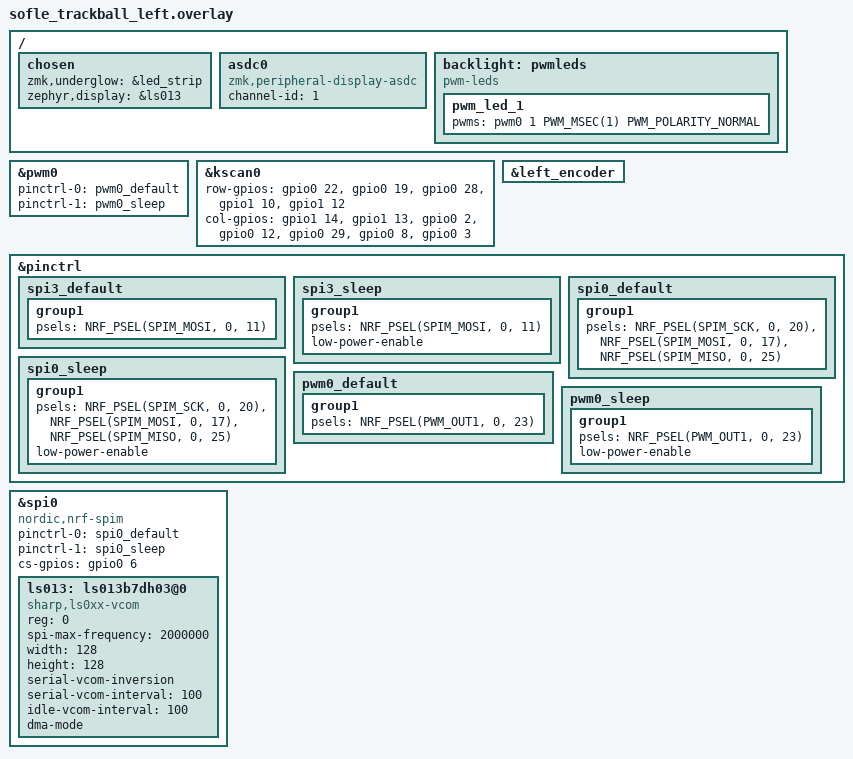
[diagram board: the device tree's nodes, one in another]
/*
 * Copyright (c) 2020 ZMK Contributors
 *
 * SPDX-License-Identifier: MIT
 */
#include <dt-bindings/zmk/input_transform.h>
#include <dt-bindings/led/led.h>
#include <behaviors/battery_history_request.dtsi>
#include "sofle_trackball.dtsi"

#include "rgb.dtsi"



/ {
    chosen {
        zmk,underglow = &led_strip;
        zephyr,display = &ls013;
    };

    asdc0: asdc0 {
        compatible = "zmk,peripheral-display-asdc";
        channel-id = <1>;
        status = "okay";
    };
backlight: pwmleds {
    compatible = "pwm-leds";
   // pwm_led_0: pwm_led_0 {
   //     pwms = <&pwm0 0 PWM_MSEC(1) PWM_POLARITY_NORMAL>;
  //  };
    pwm_led_1: pwm_led_1 {
        pwms = <&pwm0 1 PWM_MSEC(1) PWM_POLARITY_NORMAL>;
    };
  //  pwm_led_2: pwm_led_2 {
   //     pwms = <&pwm0 2 PWM_MSEC(1) PWM_POLARITY_NORMAL>;
  //  };
};


};

&pwm0 {
    status = "okay";
    pinctrl-0 = <&pwm0_default>;
    pinctrl-1 = <&pwm0_sleep>;
    pinctrl-names = "default", "sleep";
};
&kscan0 {
    row-gpios
                = <&gpio0 22 (GPIO_ACTIVE_HIGH | GPIO_PULL_DOWN)>
                , <&gpio0 19 (GPIO_ACTIVE_HIGH | GPIO_PULL_DOWN)>
                , <&gpio0 28 (GPIO_ACTIVE_HIGH | GPIO_PULL_DOWN)>
                , <&gpio1 10 (GPIO_ACTIVE_HIGH | GPIO_PULL_DOWN)>
                , <&gpio1 12 (GPIO_ACTIVE_HIGH | GPIO_PULL_DOWN)>
    ;
    col-gpios
                = <&gpio1 14 (GPIO_ACTIVE_HIGH)>
                , <&gpio1 13 (GPIO_ACTIVE_HIGH)>
                , <&gpio0 2 (GPIO_ACTIVE_HIGH)>
                , <&gpio0 12 (GPIO_ACTIVE_HIGH)>
                , <&gpio0 29 (GPIO_ACTIVE_HIGH)>
                , <&gpio0 8 (GPIO_ACTIVE_HIGH)>
                , <&gpio0 3 (GPIO_ACTIVE_HIGH)>
    ;
};




&left_encoder {
    status = "okay";
};



&pinctrl {

    spi3_default: spi3_default {
        group1 {
            psels = <NRF_PSEL(SPIM_MOSI, 0, 11)>;
        };
    };
    spi3_sleep: spi3_sleep {
        group1 {
            psels = <NRF_PSEL(SPIM_MOSI, 0, 11)>;
            low-power-enable;
        };
    };
    spi0_default: spi0_default {
        group1 {
            psels = <NRF_PSEL(SPIM_SCK, 0, 20)>,
                <NRF_PSEL(SPIM_MOSI, 0, 17)>,
                <NRF_PSEL(SPIM_MISO, 0, 25)>;
        };
    };

    spi0_sleep: spi0_sleep {
        group1 {
            psels = <NRF_PSEL(SPIM_SCK, 0, 20)>,
                <NRF_PSEL(SPIM_MOSI, 0, 17)>,
                <NRF_PSEL(SPIM_MISO, 0, 25)>;
            low-power-enable;
        };
    };
    // Other Pinctrl definitions go here
    pwm0_default: pwm0_default {
        group1 {
            psels =  <NRF_PSEL(PWM_OUT1, 0, 23)>; 
               
        };
    };
    pwm0_sleep: pwm0_sleep {
        group1 {
            psels =  <NRF_PSEL(PWM_OUT1, 0, 23)>; 
                  
            low-power-enable;
        };
    };

};





nice_view_spi: &spi0 {
    status = "okay";
    compatible = "nordic,nrf-spim";
    pinctrl-0 = <&spi0_default>;
    pinctrl-1 = <&spi0_sleep>;
    pinctrl-names = "default", "sleep";
    cs-gpios = <&gpio0 6 GPIO_ACTIVE_HIGH>;
    ls013: ls013b7dh03@0 {
        compatible = "sharp,ls0xx-vcom";
        reg = <0>;
        spi-max-frequency = <2000000>;
        width = <128>;
        height = <128>;
        serial-vcom-inversion;
        /* Diagnostic: was 17ms. The vcom driver's toggle work item and the
         * LVGL flush path fight over the same SPI bus semaphore (240ms
         * timeout) every cycle; at 17ms that's ~59 arbitrations/sec forever
         * while the screen is active. Testing whether relaxing this makes
         * the ~12.5s freeze go away or shift. */
        serial-vcom-interval = <100>;
        idle-vcom-interval = <100>;
        dma-mode;
    };
};

